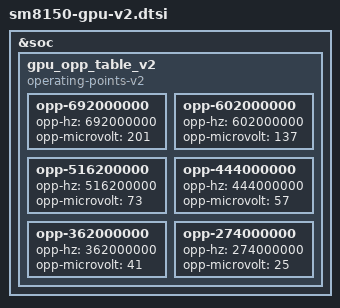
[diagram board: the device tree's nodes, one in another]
/* Copyright (c) 2018-2019, The Linux Foundation. All rights reserved.
 *
 * This program is free software; you can redistribute it and/or modify
 * it under the terms of the GNU General Public License version 2 and
 * only version 2 as published by the Free Software Foundation.
 *
 * This program is distributed in the hope that it will be useful,
 * but WITHOUT ANY WARRANTY; without even the implied warranty of
 * MERCHANTABILITY or FITNESS FOR A PARTICULAR PURPOSE.  See the
 * GNU General Public License for more details.
 */

&soc {
	gpu_opp_table_v2: gpu_opp_table_v2 {
		compatible = "operating-points-v2";

		opp-692000000 {
			opp-hz = /bits/ 64 <692000000>;
			opp-microvolt = <201>;
		};

		opp-602000000 {
			opp-hz = /bits/ 64 <602000000>;
			opp-microvolt = <137>;
		};

		opp-516200000 {
			opp-hz = /bits/ 64 <516200000>;
			opp-microvolt = <73>;
		};

		opp-444000000 {
			opp-hz = /bits/ 64 <444000000>;
			opp-microvolt = <57>;
		};

		opp-362000000 {
			opp-hz = /bits/ 64 <362000000>;
			opp-microvolt = <41>;
		};

		opp-274000000 {
			opp-hz = /bits/ 64 <274000000>;
			opp-microvolt = <25>;
		};
	};
};
